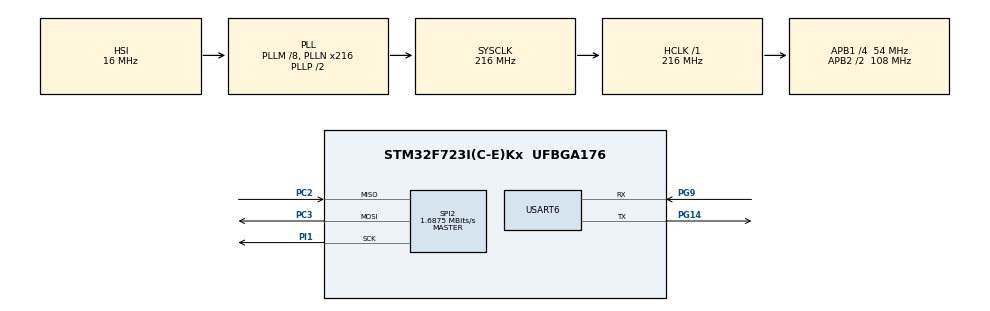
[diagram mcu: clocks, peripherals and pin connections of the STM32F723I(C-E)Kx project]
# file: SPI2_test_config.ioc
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CORTEX_M7.CPU_ICache=Disabled
CORTEX_M7.PREFETCH_ENABLE=0
Mcu.Family=STM32F7
Mcu.Name=STM32F723I(C-E)Kx
Mcu.Package=UFBGA176
NVIC.PriorityGroup=NVIC_PRIORITYGROUP_4
NVIC.TIM1_UP_TIM10_IRQn=true\:0\:0\:false\:false\:true\:false
NVIC.TimeBase=TIM1_UP_TIM10_IRQn
NVIC.TimeBaseIP=TIM1
PA13.Mode=Serial_Wire
PA13.Signal=SYS_JTMS-SWDIO
PA14.Mode=Serial_Wire
PA14.Signal=SYS_JTCK-SWCLK
PC2.Mode=Full_Duplex_Master
PC2.Signal=SPI2_MISO
PC3.Mode=Full_Duplex_Master
PC3.Signal=SPI2_MOSI
PG14.Mode=Asynchronous
PG14.Signal=USART6_TX
PG9.Mode=Asynchronous
PG9.Signal=USART6_RX
PH0-OSC_IN.Mode=HSE-External-Oscillator
PH0-OSC_IN.Signal=RCC_OSC_IN
PH1-OSC_OUT.Mode=HSE-External-Oscillator
PH1-OSC_OUT.Signal=RCC_OSC_OUT
PI1.Mode=Full_Duplex_Master
PI1.Signal=SPI2_SCK
ProjectManager.HeapSize=0x200
ProjectManager.StackSize=0x400
ProjectManager.TargetToolchain=SW4STM32
RCC.AHBFreq_Value=216000000
RCC.APB1CLKDivider=RCC_HCLK_DIV4
RCC.APB1Freq_Value=54000000
RCC.APB1TimFreq_Value=108000000
RCC.APB2CLKDivider=RCC_HCLK_DIV2
RCC.APB2Freq_Value=108000000
RCC.APB2TimFreq_Value=216000000
RCC.CortexFreq_Value=216000000
RCC.HCLKFreq_Value=216000000
RCC.HSE_VALUE=25000000
RCC.HSI_VALUE=16000000
RCC.LSE_VALUE=32768
RCC.PLLM=8
RCC.PLLN=216
RCC.PLLQ=9
RCC.SYSCLKFreq_VALUE=216000000
RCC.SYSCLKSource=RCC_SYSCLKSOURCE_PLLCLK
RCC.USBFreq_Value=48000000
RCC.VCOOutputFreq_Value=432000000
SPI2.BaudRatePrescaler=SPI_BAUDRATEPRESCALER_32
SPI2.CalculateBaudRate=1.6875 MBits/s
SPI2.Direction=SPI_DIRECTION_2LINES
SPI2.Mode=SPI_MODE_MASTER
SPI2.VirtualType=VM_MASTER
USART6.VirtualMode-Asynchronous=VM_ASYNC
VP_SYS_VS_tim1.Mode=TIM1
board=32F723EDISCOVERY

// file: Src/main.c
/**
  ******************************************************************************
  * @file           : main.c
  * @brief          : Main program body
  ******************************************************************************
  ** This notice applies to any and all portions of this file
  * that are not between comment pairs USER CODE BEGIN and
  * USER CODE END. Other portions of this file, whether
  * inserted by the user or by software development tools
  * are owned by their respective copyright owners.
  *
  * COPYRIGHT(c) 2018 STMicroelectronics
  *
  * Redistribution and use in source and binary forms, with or without modification,
  * are permitted provided that the following conditions are met:
  *   1. Redistributions of source code must retain the above copyright notice,
  *      this list of conditions and the following disclaimer.
  *   2. Redistributions in binary form must reproduce the above copyright notice,
  *      this list of conditions and the following disclaimer in the documentation
  *      and/or other materials provided with the distribution.
  *   3. Neither the name of STMicroelectronics nor the names of its contributors
  *      may be used to endorse or promote products derived from this software
  *      without specific prior written permission.
  *
  * THIS SOFTWARE IS PROVIDED BY THE COPYRIGHT HOLDERS AND CONTRIBUTORS "AS IS"
  * AND ANY EXPRESS OR IMPLIED WARRANTIES, INCLUDING, BUT NOT LIMITED TO, THE
  * IMPLIED WARRANTIES OF MERCHANTABILITY AND FITNESS FOR A PARTICULAR PURPOSE ARE
  * DISCLAIMED. IN NO EVENT SHALL THE COPYRIGHT HOLDER OR CONTRIBUTORS BE LIABLE
  * FOR ANY DIRECT, INDIRECT, INCIDENTAL, SPECIAL, EXEMPLARY, OR CONSEQUENTIAL
  * DAMAGES (INCLUDING, BUT NOT LIMITED TO, PROCUREMENT OF SUBSTITUTE GOODS OR
  * SERVICES; LOSS OF USE, DATA, OR PROFITS; OR BUSINESS INTERRUPTION) HOWEVER
  * CAUSED AND ON ANY THEORY OF LIABILITY, WHETHER IN CONTRACT, STRICT LIABILITY,
  * OR TORT (INCLUDING NEGLIGENCE OR OTHERWISE) ARISING IN ANY WAY OUT OF THE USE
  * OF THIS SOFTWARE, EVEN IF ADVISED OF THE POSSIBILITY OF SUCH DAMAGE.
  *
  ******************************************************************************
  */
#include "main.h"
#include "stm32f7xx_hal.h"

SPI_HandleTypeDef hspi2;

UART_HandleTypeDef huart6;

/* USER CODE BEGIN PV */
/* Private variables ---------------------------------------------------------*/

/* USER CODE END PV */

void SystemClock_Config(void);
static void MX_GPIO_Init(void);
static void MX_SPI2_Init(void);
static void MX_USART6_UART_Init(void);

/* USER CODE BEGIN PFP */
/* Private function prototypes -----------------------------------------------*/

/* USER CODE END PFP */

int main(void)
{

  /* MCU Configuration----------------------------------------------------------*/

  /* Reset of all peripherals, Initializes the Flash interface and the Systick. */
  HAL_Init();

  /* Configure the system clock */
  SystemClock_Config();

  /* Initialize all configured peripherals */
  MX_GPIO_Init();
  MX_SPI2_Init();
  MX_USART6_UART_Init();

  /* Infinite loop */
  /* USER CODE BEGIN WHILE */
  while (1)
  {

	  uint8_t spiTxBuf[1];
	  spiTxBuf[0] = 0b11011101;//|0b10100000;
	  uint8_t spiRxBuf[2];
	  uint16_t txSize=sizeof(spiTxBuf);

	  //SPI Receipt
	  //1.Bring slave select low
	  HAL_GPIO_WritePin(GPIOC, GPIO_PIN_3, GPIO_PIN_RESET);
	  //2.Transmit register + 0x80(to set most significant bit to high to enable read mode )

	  HAL_SPI_Transmit(&hspi2,spiTxBuf,1,50);
	  //3.Receive data
	  HAL_SPI_Receive(&hspi2,spiRxBuf,1,50);
	  //4.Bring slave select high
	  HAL_GPIO_WritePin(GPIOC, GPIO_PIN_3, GPIO_PIN_SET);

	  HAL_UART_Transmit(&huart6, spiTxBuf, txSize, 50);
	  /* Infinite loop */
	  /* USER CODE BEGIN WHILE */

  /* USER CODE END WHILE */

  }

}

void SystemClock_Config(void)
{

  RCC_OscInitTypeDef RCC_OscInitStruct;
  RCC_ClkInitTypeDef RCC_ClkInitStruct;
  RCC_PeriphCLKInitTypeDef PeriphClkInitStruct;

    /**Configure the main internal regulator output voltage
    */
  __HAL_RCC_PWR_CLK_ENABLE();

  __HAL_PWR_VOLTAGESCALING_CONFIG(PWR_REGULATOR_VOLTAGE_SCALE1);

    /**Initializes the CPU, AHB and APB busses clocks
    */
  RCC_OscInitStruct.OscillatorType = RCC_OSCILLATORTYPE_HSI;
  RCC_OscInitStruct.HSIState = RCC_HSI_ON;
  RCC_OscInitStruct.HSICalibrationValue = 16;
  RCC_OscInitStruct.PLL.PLLState = RCC_PLL_ON;
  RCC_OscInitStruct.PLL.PLLSource = RCC_PLLSOURCE_HSI;
  RCC_OscInitStruct.PLL.PLLM = 8;
  RCC_OscInitStruct.PLL.PLLN = 216;
  RCC_OscInitStruct.PLL.PLLP = RCC_PLLP_DIV2;
  RCC_OscInitStruct.PLL.PLLQ = 9;
  if (HAL_RCC_OscConfig(&RCC_OscInitStruct) != HAL_OK)
  {
    _Error_Handler(__FILE__, __LINE__);
  }

    /**Activate the Over-Drive mode
    */
  if (HAL_PWREx_EnableOverDrive() != HAL_OK)
  {
    _Error_Handler(__FILE__, __LINE__);
  }

    /**Initializes the CPU, AHB and APB busses clocks
    */
  RCC_ClkInitStruct.ClockType = RCC_CLOCKTYPE_HCLK|RCC_CLOCKTYPE_SYSCLK
                              |RCC_CLOCKTYPE_PCLK1|RCC_CLOCKTYPE_PCLK2;
  RCC_ClkInitStruct.SYSCLKSource = RCC_SYSCLKSOURCE_PLLCLK;
  RCC_ClkInitStruct.AHBCLKDivider = RCC_SYSCLK_DIV1;
  RCC_ClkInitStruct.APB1CLKDivider = RCC_HCLK_DIV4;
  RCC_ClkInitStruct.APB2CLKDivider = RCC_HCLK_DIV2;

  if (HAL_RCC_ClockConfig(&RCC_ClkInitStruct, FLASH_LATENCY_7) != HAL_OK)
  {
    _Error_Handler(__FILE__, __LINE__);
  }

  PeriphClkInitStruct.PeriphClockSelection = RCC_PERIPHCLK_USART6;
  PeriphClkInitStruct.Usart6ClockSelection = RCC_USART6CLKSOURCE_PCLK2;
  if (HAL_RCCEx_PeriphCLKConfig(&PeriphClkInitStruct) != HAL_OK)
  {
    _Error_Handler(__FILE__, __LINE__);
  }

    /**Configure the Systick interrupt time
    */
  HAL_SYSTICK_Config(HAL_RCC_GetHCLKFreq()/1000);

    /**Configure the Systick
    */
  HAL_SYSTICK_CLKSourceConfig(SYSTICK_CLKSOURCE_HCLK);

  /* SysTick_IRQn interrupt configuration */
  HAL_NVIC_SetPriority(SysTick_IRQn, 0, 0);
}

/* SPI2 init function */
static void MX_SPI2_Init(void)
{

  /* SPI2 parameter configuration*/
  hspi2.Instance = SPI2;
  hspi2.Init.Mode = SPI_MODE_MASTER;
  hspi2.Init.Direction = SPI_DIRECTION_2LINES;
  hspi2.Init.DataSize = SPI_DATASIZE_4BIT;
  hspi2.Init.CLKPolarity = SPI_POLARITY_LOW;
  hspi2.Init.CLKPhase = SPI_PHASE_1EDGE;
  hspi2.Init.NSS = SPI_NSS_SOFT;
  hspi2.Init.BaudRatePrescaler = SPI_BAUDRATEPRESCALER_32;
  hspi2.Init.FirstBit = SPI_FIRSTBIT_MSB;
  hspi2.Init.TIMode = SPI_TIMODE_DISABLE;
  hspi2.Init.CRCCalculation = SPI_CRCCALCULATION_DISABLE;
  hspi2.Init.CRCPolynomial = 7;
  hspi2.Init.CRCLength = SPI_CRC_LENGTH_DATASIZE;
  hspi2.Init.NSSPMode = SPI_NSS_PULSE_ENABLE;
  if (HAL_SPI_Init(&hspi2) != HAL_OK)
  {
    _Error_Handler(__FILE__, __LINE__);
  }

}

/* USART6 init function */
static void MX_USART6_UART_Init(void)
{

  huart6.Instance = USART6;
  huart6.Init.BaudRate = 115200;
  huart6.Init.WordLength = UART_WORDLENGTH_8B;
  huart6.Init.StopBits = UART_STOPBITS_1;
  huart6.Init.Parity = UART_PARITY_NONE;
  huart6.Init.Mode = UART_MODE_TX_RX;
  huart6.Init.HwFlowCtl = UART_HWCONTROL_NONE;
  huart6.Init.OverSampling = UART_OVERSAMPLING_16;
  huart6.Init.OneBitSampling = UART_ONE_BIT_SAMPLE_DISABLE;
  huart6.AdvancedInit.AdvFeatureInit = UART_ADVFEATURE_NO_INIT;
  if (HAL_UART_Init(&huart6) != HAL_OK)
  {
    _Error_Handler(__FILE__, __LINE__);
  }

}

/** Configure pins as
        * Analog
        * Input
        * Output
        * EVENT_OUT
        * EXTI
*/
static void MX_GPIO_Init(void)
{

  /* GPIO Ports Clock Enable */
  __HAL_RCC_GPIOG_CLK_ENABLE();
  __HAL_RCC_GPIOA_CLK_ENABLE();
  __HAL_RCC_GPIOI_CLK_ENABLE();
  __HAL_RCC_GPIOH_CLK_ENABLE();
  __HAL_RCC_GPIOC_CLK_ENABLE();

}

void HAL_TIM_PeriodElapsedCallback(TIM_HandleTypeDef *htim)
{
  if (htim->Instance == TIM1) {
    HAL_IncTick();
  }
}

void _Error_Handler(char *file, int line)
{
  while(1)
  {
  }
}

/************************ (C) COPYRIGHT STMicroelectronics *****END OF FILE****/
